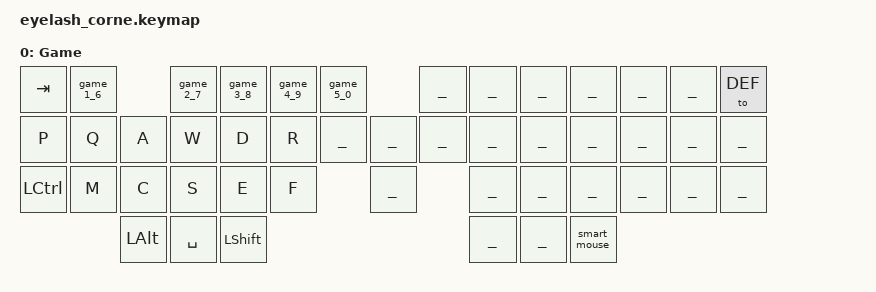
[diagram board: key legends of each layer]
#define CONFIG_WIRELESS

// 6th layer
#define GAME 6 

#define ZMK_BASE_LAYER(name, LT, RT, LM, RM, LB, RB, LH, RH)     \
    ZMK_LAYER(                                                   \
        name,                                                    \
        &none LT                 &none        RT &to GAME        \
        &none LM           &none &none &none  RM &none           \
        &none LB                 &none        RB &none           \
        &none LH RH &smart_mouse  )


#include "eyelash42-no-enc.h"
#include "base.keymap"

// Geeksville add game layer

// Game layer: Replaces left 3x6 + three thumb keys with gaming layout.
// Number keys 1-5 shift to 6-0 when shift is held.
SIMPLE_MORPH(game_1_6, SFT, &kp N1, &kp N6)
SIMPLE_MORPH(game_2_7, SFT, &kp N2, &kp N7)
SIMPLE_MORPH(game_3_8, SFT, &kp N3, &kp N8)
SIMPLE_MORPH(game_4_9, SFT, &kp N4, &kp N9)
SIMPLE_MORPH(game_5_0, SFT, &kp N5, &kp N0)

ZMK_LAYER(Game,
//╭──────┬──────┬──────┬──────┬──────┬──────╮                    ╭──────┬──────┬──────┬──────┬──────┬──────╮
  &kp TAB &game_1_6 &game_2_7 &game_3_8 &game_4_9 &game_5_0 ___    ___    ___    ___    ___    ___    &to DEF
//├──────┼──────┼──────┼──────┼──────┼──────┤                    ├──────┼──────┼──────┼──────┼──────┼──────┤
  &kp P  &kp Q  &kp A  &kp W  &kp D  &kp R          ___ ___ ___     ___    ___    ___    ___    ___    ___
//├──────┼──────┼──────┼──────┼──────┼──────┤                    ├──────┼──────┼──────┼──────┼──────┼──────┤
  &kp LCTRL &kp M &kp C &kp S  &kp E  &kp F             ___         ___    ___    ___    ___    ___    ___
//╰──────┴──────┴──────┼──────┼──────┼──────┤                    ├──────┼──────┼──────┼──────┴──────┴──────╯
                &kp LALT &kp SPACE &kp LSHFT                        ___    ___ &smart_mouse
//                     ╰──────┴──────┴──────╯                    ╰──────┴──────┴──────╯
)

// Geeksville add zmk-studio support
/ {
    keymap {
        compatible = "zmk,keymap";

        extra1 {
            status = "reserved";
        };

        extra2 {
            status = "reserved";
        };
    };
};
